AUTOSAR XML (schema 4.0)
package /ComponentTypes/ApplicationComponents
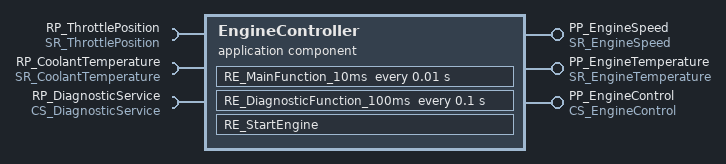
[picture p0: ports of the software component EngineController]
  application sw component type EngineController: category=APPLICATION_SW_COMPONENT
    provide port PP_EngineSpeed: provided-interface=SR_EngineSpeed
    provide port PP_EngineTemperature: provided-interface=SR_EngineTemperature
    provide port PP_EngineControl: provided-interface=CS_EngineControl
    require port RP_ThrottlePosition: required-interface=SR_ThrottlePosition
    require port RP_CoolantTemperature: required-interface=SR_CoolantTemperature
    require port RP_DiagnosticService: required-interface=CS_DiagnosticService
    provide/require port PRP_NvMService: provided-required-interface=CS_NvMService
    behavior EngineController_InternalBehavior
      runnable RE_MainFunction_10ms: minimum-start-interval=0.01
        data-read-access:
          access DA_ReadThrottle: accessed-variable=RP_ThrottlePosition.ThrottleValue
          access DA_ReadCoolant: accessed-variable=RP_CoolantTemperature.TempValue
        data-write-access:
          access DA_WriteSpeed: accessed-variable=PP_EngineSpeed.SpeedValue
          access DA_WriteTemperature: accessed-variable=PP_EngineTemperature.TempValue
      runnable RE_DiagnosticFunction_100ms: minimum-start-interval=0.1
        sync call SC_ReadDTC: operation=RP_DiagnosticService.ReadDTCInformation
      runnable RE_StartEngine
        operation invoked event OIE_StartEngine: start-on-event=RE_StartEngine, operation=PP_EngineControl.StartEngine
      timing event TE_MainFunction_10ms: start-on-event=RE_MainFunction_10ms, period=0.01
      timing event TE_DiagnosticFunction_100ms: start-on-event=RE_DiagnosticFunction_100ms, period=0.1
      exclusive area ExclusiveArea_EngineData
      per instance memory PIM_EngineState: type=Impl_EngineState
      per instance memory PIM_EngineRunTime: type=Impl_uint32
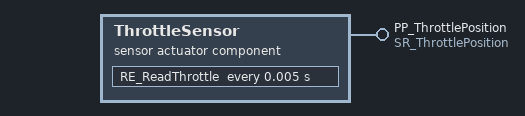
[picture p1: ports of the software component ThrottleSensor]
  sensor actuator sw component type ThrottleSensor
    provide port PP_ThrottlePosition: provided-interface=SR_ThrottlePosition
    behavior ThrottleSensor_InternalBehavior
      runnable RE_ReadThrottle: minimum-start-interval=0.005
        data-write-access:
          access DA_WriteThrottleValue: accessed-variable=PP_ThrottlePosition.ThrottleValue
      timing event TE_ReadThrottle_5ms: start-on-event=RE_ReadThrottle, period=0.005
